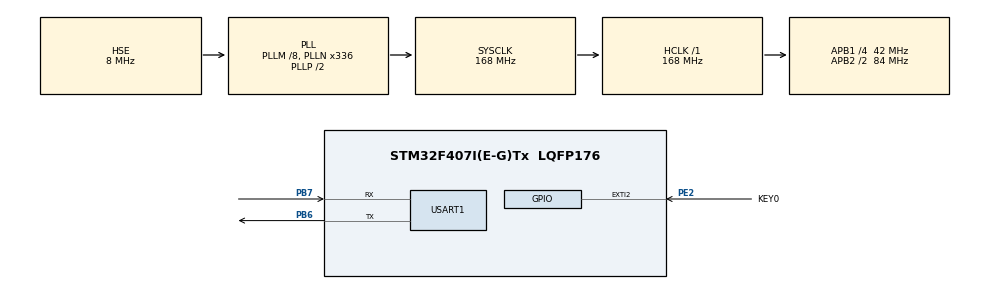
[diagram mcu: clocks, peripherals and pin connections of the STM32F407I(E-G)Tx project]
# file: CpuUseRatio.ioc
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FREERTOS.INCLUDE_vTaskDelayUntil=1
FREERTOS.Tasks01=KeyTask,0,128,Key_Task,Default,NULL,Dynamic,NULL,NULL
FREERTOS.configGENERATE_RUN_TIME_STATS=1
FREERTOS.configUSE_STATS_FORMATTING_FUNCTIONS=1
FREERTOS.configUSE_TRACE_FACILITY=1
Mcu.Family=STM32F4
Mcu.Name=STM32F407I(E-G)Tx
Mcu.Package=LQFP176
NVIC.EXTI2_IRQn=true\:5\:0\:false\:false\:true\:true\:true\:true
NVIC.PriorityGroup=NVIC_PRIORITYGROUP_4
NVIC.TIM1_UP_TIM10_IRQn=true\:0\:0\:false\:false\:true\:false\:false\:true
NVIC.TIM6_DAC_IRQn=true\:5\:0\:false\:false\:true\:true\:true\:true
NVIC.TimeBase=TIM1_UP_TIM10_IRQn
NVIC.TimeBaseIP=TIM1
PA13.Mode=Serial_Wire
PA13.Signal=SYS_JTMS-SWDIO
PA14.Mode=Serial_Wire
PA14.Signal=SYS_JTCK-SWCLK
PB6.Mode=Asynchronous
PB6.Signal=USART1_TX
PB7.Mode=Asynchronous
PB7.Signal=USART1_RX
PE2.GPIO_Label=KEY0
PE2.GPIO_ModeDefaultEXTI=GPIO_MODE_IT_FALLING
PE2.GPIO_PuPd=GPIO_PULLUP
PE2.Signal=GPXTI2
PH0-OSC_IN.Mode=HSE-External-Oscillator
PH0-OSC_IN.Signal=RCC_OSC_IN
PH1-OSC_OUT.Mode=HSE-External-Oscillator
PH1-OSC_OUT.Signal=RCC_OSC_OUT
ProjectManager.HeapSize=0x200
ProjectManager.StackSize=0x400
ProjectManager.TargetToolchain=MDK-ARM V5
RCC.48MHZClocksFreq_Value=84000000
RCC.AHBFreq_Value=168000000
RCC.APB1CLKDivider=RCC_HCLK_DIV4
RCC.APB1Freq_Value=42000000
RCC.APB1TimFreq_Value=84000000
RCC.APB2CLKDivider=RCC_HCLK_DIV2
RCC.APB2Freq_Value=84000000
RCC.APB2TimFreq_Value=168000000
RCC.CortexFreq_Value=168000000
RCC.HCLKFreq_Value=168000000
RCC.HSE_VALUE=8000000
RCC.HSI_VALUE=16000000
RCC.LSE_VALUE=32768
RCC.PLLM=8
RCC.PLLN=336
RCC.PLLSourceVirtual=RCC_PLLSOURCE_HSE
RCC.SYSCLKFreq_VALUE=168000000
RCC.SYSCLKSource=RCC_SYSCLKSOURCE_PLLCLK
RCC.VCOOutputFreq_Value=336000000
TIM6.Period=1000-1
TIM6.Prescaler=84-1
USART1.VirtualMode=VM_ASYNC
VP_FREERTOS_VS_CMSIS_V1.Mode=CMSIS_V1
VP_SYS_VS_tim1.Mode=TIM1
VP_TIM6_VS_ClockSourceINT.Mode=Enable_Timer
board=custom

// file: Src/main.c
/* USER CODE BEGIN Header */
/**
  ******************************************************************************
  * @file           : main.c
  * @brief          : Main program body
  ******************************************************************************
  * @attention
  *
  * <h2><center>&copy; Copyright (c) 2024 STMicroelectronics.
  * All rights reserved.</center></h2>
  *
  * This software component is licensed by ST under Ultimate Liberty license
  * SLA0044, the "License"; You may not use this file except in compliance with
  * the License. You may obtain a copy of the License at:
  *                             www.st.com/SLA0044
  *
  ******************************************************************************
  */
/* USER CODE END Header */

#include "main.h"
#include "cmsis_os.h"
#include "tim.h"
#include "usart.h"
#include "gpio.h"

void SystemClock_Config(void);
void MX_FREERTOS_Init(void);
/* USER CODE BEGIN PFP */
extern uint32_t timecount;
/* USER CODE END PFP */

int main(void)
{

  /* MCU Configuration--------------------------------------------------------*/

  /* Reset of all peripherals, Initializes the Flash interface and the Systick. */
  HAL_Init();

  /* Configure the system clock */
  SystemClock_Config();

  /* Initialize all configured peripherals */
  MX_GPIO_Init();
  MX_TIM6_Init();
  MX_USART1_UART_Init();

  /* Call init function for freertos objects (in freertos.c) */
  MX_FREERTOS_Init();

  /* Start scheduler */
  osKernelStart();

  /* We should never get here as control is now taken by the scheduler */

  /* Infinite loop */
  while (1)
  {

  }
}

void SystemClock_Config(void)
{
  RCC_OscInitTypeDef RCC_OscInitStruct = {0};
  RCC_ClkInitTypeDef RCC_ClkInitStruct = {0};

  /** Configure the main internal regulator output voltage
  */
  __HAL_RCC_PWR_CLK_ENABLE();
  __HAL_PWR_VOLTAGESCALING_CONFIG(PWR_REGULATOR_VOLTAGE_SCALE1);
  /** Initializes the CPU, AHB and APB busses clocks
  */
  RCC_OscInitStruct.OscillatorType = RCC_OSCILLATORTYPE_HSE;
  RCC_OscInitStruct.HSEState = RCC_HSE_ON;
  RCC_OscInitStruct.PLL.PLLState = RCC_PLL_ON;
  RCC_OscInitStruct.PLL.PLLSource = RCC_PLLSOURCE_HSE;
  RCC_OscInitStruct.PLL.PLLM = 8;
  RCC_OscInitStruct.PLL.PLLN = 336;
  RCC_OscInitStruct.PLL.PLLP = RCC_PLLP_DIV2;
  RCC_OscInitStruct.PLL.PLLQ = 4;
  if (HAL_RCC_OscConfig(&RCC_OscInitStruct) != HAL_OK)
  {
    Error_Handler();
  }
  /** Initializes the CPU, AHB and APB busses clocks
  */
  RCC_ClkInitStruct.ClockType = RCC_CLOCKTYPE_HCLK|RCC_CLOCKTYPE_SYSCLK
                              |RCC_CLOCKTYPE_PCLK1|RCC_CLOCKTYPE_PCLK2;
  RCC_ClkInitStruct.SYSCLKSource = RCC_SYSCLKSOURCE_PLLCLK;
  RCC_ClkInitStruct.AHBCLKDivider = RCC_SYSCLK_DIV1;
  RCC_ClkInitStruct.APB1CLKDivider = RCC_HCLK_DIV4;
  RCC_ClkInitStruct.APB2CLKDivider = RCC_HCLK_DIV2;

  if (HAL_RCC_ClockConfig(&RCC_ClkInitStruct, FLASH_LATENCY_5) != HAL_OK)
  {
    Error_Handler();
  }
}

void HAL_TIM_PeriodElapsedCallback(TIM_HandleTypeDef *htim)
{
  if (htim->Instance == TIM1) {
    HAL_IncTick();
  }
  /* USER CODE BEGIN Callback 1 */
  if (htim->Instance == TIM6) {
    timecount++;
  }
  /* USER CODE END Callback 1 */
}

void Error_Handler(void)
{
}

/************************ (C) COPYRIGHT STMicroelectronics *****END OF FILE****/

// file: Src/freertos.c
/* USER CODE BEGIN Header */
/**
  ******************************************************************************
  * File Name          : freertos.c
  * Description        : Code for freertos applications
  ******************************************************************************
  * @attention
  *
  * <h2><center>&copy; Copyright (c) 2024 STMicroelectronics.
  * All rights reserved.</center></h2>
  *
  * This software component is licensed by ST under Ultimate Liberty license
  * SLA0044, the "License"; You may not use this file except in compliance with
  * the License. You may obtain a copy of the License at:
  *                             www.st.com/SLA0044
  *
  ******************************************************************************
  */
/* USER CODE END Header */

#include "FreeRTOS.h"
#include "task.h"
#include "main.h"
#include "cmsis_os.h"

/* USER CODE BEGIN Includes */
#include "tim.h"
#include "gpio.h"
#include "string.h"
/* USER CODE END Includes */

/* USER CODE BEGIN PD */
uint8_t TlBuff[400];
extern teKeyStatus KStatus;
extern uint32_t timecount;
/* USER CODE END PD */

/* USER CODE BEGIN PM */
extern uint32_t timecount;

/* USER CODE END PM */

osThreadId KeyTaskHandle;

void Key_Task(void const * argument);

void MX_FREERTOS_Init(void); /* (MISRA C 2004 rule 8.1) */

/* GetIdleTaskMemory prototype (linked to static allocation support) */
void vApplicationGetIdleTaskMemory( StaticTask_t **ppxIdleTaskTCBBuffer, StackType_t **ppxIdleTaskStackBuffer, uint32_t *pulIdleTaskStackSize );

/* Hook prototypes */
void configureTimerForRunTimeStats(void);
unsigned long getRunTimeCounterValue(void);

/* USER CODE BEGIN 1 */
/* Functions needed when configGENERATE_RUN_TIME_STATS is on */
__weak void configureTimerForRunTimeStats(void)
{
	//1. 开启定时器6的中断——启动定时器
	//2. 定时器统计值，初始化为0
	HAL_TIM_Base_Start_IT(&htim6);  //Turn on the interrupt of the timer  参数1：TIM_HandleTypeDef* 类型的定时器句柄指针(在tim.c中)
	timecount = 0ul;                //Initialized to an unsigned long integer
}

__weak unsigned long getRunTimeCounterValue(void)
{
	return timecount;
}
/* USER CODE END 1 */

/* USER CODE BEGIN GET_IDLE_TASK_MEMORY */
static StaticTask_t xIdleTaskTCBBuffer;
static StackType_t xIdleStack[configMINIMAL_STACK_SIZE];

void vApplicationGetIdleTaskMemory( StaticTask_t **ppxIdleTaskTCBBuffer, StackType_t **ppxIdleTaskStackBuffer, uint32_t *pulIdleTaskStackSize )
{
  *ppxIdleTaskTCBBuffer = &xIdleTaskTCBBuffer;
  *ppxIdleTaskStackBuffer = &xIdleStack[0];
  *pulIdleTaskStackSize = configMINIMAL_STACK_SIZE;
  /* place for user code */
}
/* USER CODE END GET_IDLE_TASK_MEMORY */

void MX_FREERTOS_Init(void) {

  /* Create the thread(s) */
  /* definition and creation of KeyTask */
  osThreadDef(KeyTask, Key_Task, osPriorityNormal, 0, 128);
  KeyTaskHandle = osThreadCreate(osThread(KeyTask), NULL);

}

void Key_Task(void const * argument)
{

  /* USER CODE BEGIN Key_Task */
  /* Infinite loop */
	KStatus = KEY_RESET;
  for(;;)
  {//The suspend and resume of the LED is realized according to the key flag bit
    if(KStatus == KEY_DOWN)
		{
			taskENTER_CRITICAL();
			memset(TlBuff, 0, 400);
			vTaskGetRunTimeStats((char *)TlBuff);
			printf("name,   abs time   time\n");
			printf("-------------------------------------------------------\n");
			printf("%s\n",TlBuff);
			KStatus = KEY_RESET;//Flag bit reset
			taskEXIT_CRITICAL();
		}
		if(KStatus == KEY_UP)
		{
			KStatus = KEY_RESET;
		}
		osDelay(1000);
  }
  /* USER CODE END Key_Task */
}

/************************ (C) COPYRIGHT STMicroelectronics *****END OF FILE****/
